# AT90PWM3 device description
Architecture: AVR8; Family: megaAVR
Registers are 8-bit, access not given, no defined reset value unless marked. A register's access mark holds for its fields unless they carry their own. Offsets are from the block's base; [hi:lo] are bit positions; {n}, {i} and the like mark numbered series.

## ADC — Analog-to-Digital Converter
Instances: ADC 0x00
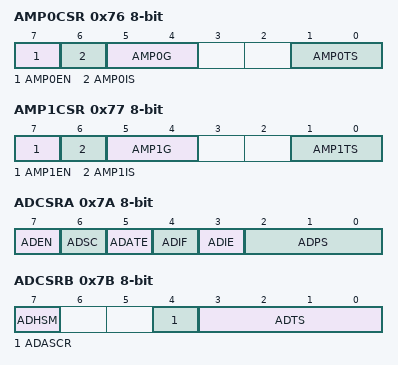
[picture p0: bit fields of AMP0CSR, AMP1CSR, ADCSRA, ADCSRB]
0x76 AMP0CSR
  [7] AMP0EN, [6] AMP0IS, [5:4] AMP0G, [1:0] AMP0TS
0x77 AMP1CSR
  [7] AMP1EN, [6] AMP1IS, [5:4] AMP1G, [1:0] AMP1TS
0x78 ADC 16-bit — ADC Data Register Bytes
  [15:0] ADC — ADC Data Register
0x7A ADCSRA — The ADC Control and Status register
  [7] ADEN — ADC Enable
  [6] ADSC — ADC Start Conversion
  [5] ADATE — ADC Auto Trigger Enable
  [4] ADIF — ADC Interrupt Flag
  [3] ADIE — ADC Interrupt Enable
  [2:0] ADPS — ADC Prescaler Select Bits
0x7B ADCSRB — ADC Control and Status Register B
  [7] ADHSM — ADC High Speed Mode
  [4] ADASCR — Amplified Channel Start Conversion
  [3:0] ADTS — ADC Auto Trigger Source
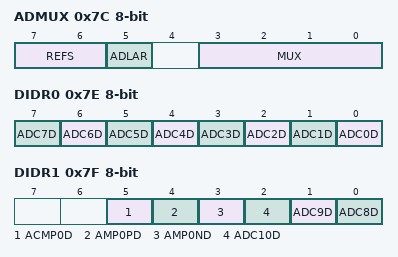
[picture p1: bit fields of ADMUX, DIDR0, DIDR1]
0x7C ADMUX — The ADC multiplexer Selection Register
  [7:6] REFS — Reference Selection Bits
    0=AREF_INTERNAL_VREF_TURNED_OFF; 1=AVCC_WITH_EXTERNAL_CAPACITOR_AT_AREF_PIN; 3=INTERNAL_2_56V_VOLTAGE_REFERENCE_WITH_EXTERNAL_CAPACITOR_AT_AREF_PIN
  [5] ADLAR — Left Adjust Result
  [3:0] MUX — Analog Channel and Gain Selection Bits
0x7E DIDR0 — Digital Input Disable Register 0
  [n] ADC{n}D (n=0..7)
0x7F DIDR1 — Digital Input Disable Register 1
  [5] ACMP0D, [4] AMP0PD, [3] AMP0ND, [2] ADC10D, [1] ADC9D, [0] ADC8D

## USART
Instances: USART 0x00
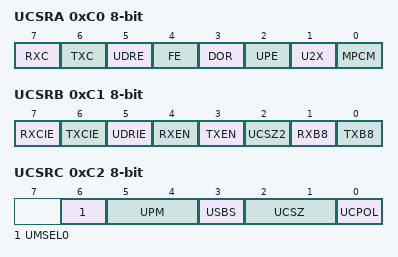
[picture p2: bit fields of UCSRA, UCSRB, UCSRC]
0xC0 UCSRA — USART Control and Status register A
  [7] RXC ro — USART Receive Complete
  [6] TXC — USART Transmit Complete
  [5] UDRE ro — USART Data Register Empty
  [4] FE ro — Framing Error
  [3] DOR ro — Data Overrun
  [2] UPE ro — USART Parity Error
  [1] U2X — Double USART Transmission Bit
  [0] MPCM — Multi-processor Communication Mode
0xC1 UCSRB — USART Control an Status register B
  [7] RXCIE — RX Complete Interrupt Enable
  [6] TXCIE — TX Complete Interrupt Enable
  [5] UDRIE — USART Data Register Empty Interrupt Enable
  [4] RXEN — Receiver Enable
  [3] TXEN — Transmitter Enable
  [2] UCSZ2 — Character Size
  [1] RXB8 — Receive Data Bit 8
  [0] TXB8 — Transmit Data Bit 8
0xC2 UCSRC — USART Control an Status register C
  [6] UMSEL0 — USART Mode Select
  [5:4] UPM — Parity Mode Bits
    0=DISABLED; 2=ENABLED_EVEN_PARITY; 3=ENABLED_ODD_PARITY
  [3] USBS — Stop Bit Select
    0=1_BIT; 1=2_BIT
  [2:1] UCSZ — Character Size Bits
  [0] UCPOL — Clock Polarity
0xC4 UBRR 16-bit — USART Baud Rate Register
  [11:0] UBRR — USART Baud Rate Register Bits
0xC6 UDR — USART I/O Data Register
  [7:0] UDR — USART I/O Data

## SPI — Serial Peripheral Interface
Instances: SPI 0x00
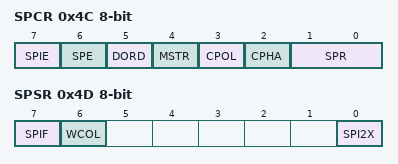
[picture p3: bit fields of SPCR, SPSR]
0x4C SPCR — SPI Control Register
  [7] SPIE — SPI Interrupt Enable
  [6] SPE — SPI Enable
  [5] DORD — Data Order
  [4] MSTR — Master/Slave Select
  [3] CPOL — Clock polarity
  [2] CPHA — Clock Phase
  [1:0] SPR — SPI Clock Rate Selects
    0=FOSC_4; 1=FOSC_16; 2=FOSC_64; 3=FOSC_128; 4=FOSC_2; 5=FOSC_8; 6=FOSC_32; 7=FOSC_64
0x4D SPSR — SPI Status Register
  [7] SPIF — SPI Interrupt Flag
  [6] WCOL — Write Collision Flag
  [0] SPI2X — Double SPI Speed Bit
0x4E SPDR — SPI Data Register
  [7:0] SPD — SPI Data bits

## WDT — Watchdog Timer
Instances: WDT 0x00
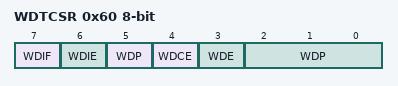
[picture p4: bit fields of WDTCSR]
0x60 WDTCSR — Watchdog Timer Control Register
  [7] WDIF — Watchdog Timeout Interrupt Flag
  [6] WDIE — Watchdog Timeout Interrupt Enable
  [4] WDCE — Watchdog Change Enable
  [3] WDE — Watch Dog Enable
  [5,2:0] WDP — Watchdog Timer Prescaler Bits
    0=OSCILLATOR_CYCLES_2K; 1=OSCILLATOR_CYCLES_4K; 2=OSCILLATOR_CYCLES_8K; 3=OSCILLATOR_CYCLES_16K; 4=OSCILLATOR_CYCLES_32K; 5=OSCILLATOR_CYCLES_64K; 6=OSCILLATOR_CYCLES_128K; 7=OSCILLATOR_CYCLES_256K; 8=OSCILLATOR_CYCLES_512K; 9=OSCILLATOR_CYCLES_1024K

## EXINT — External Interrupts
Instances: EXINT 0x00
0x3C EIFR — External Interrupt Flag Register
  [3:0] INTF — External Interrupt Flags
0x3D EIMSK — External Interrupt Mask Register
  [3:0] INT — External Interrupt Request Enable
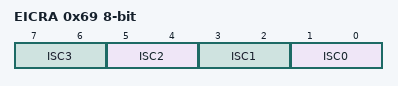
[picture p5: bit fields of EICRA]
0x69 EICRA — External Interrupt Control Register A
  [all] fields
    0=LOW_LEVEL_OF_INTX; 1=ANY_LOGICAL_CHANGE_OF_INTX; 2=FALLING_EDGE_OF_INTX; 3=RISING_EDGE_OF_INTX
  [2n+1:2n] ISC{n} (n=0..3) — External Interrupt Sense Control Bit
